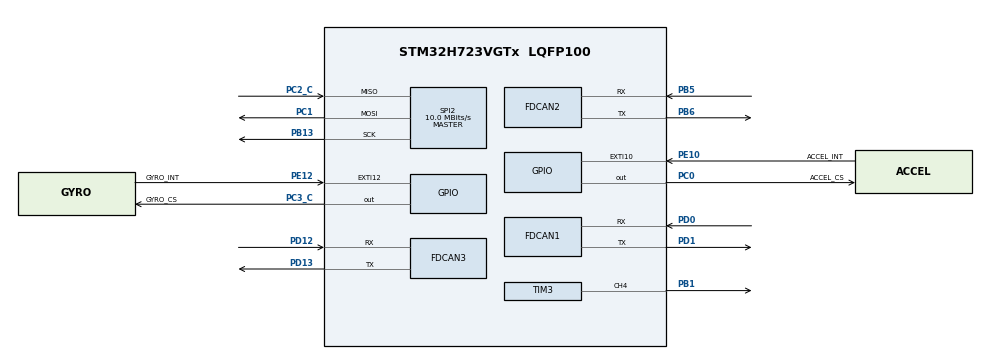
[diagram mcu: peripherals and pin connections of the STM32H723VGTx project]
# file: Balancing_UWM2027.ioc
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CORTEX_M7.AccessPermission_Spec=MPU_REGION_FULL_ACCESS
CORTEX_M7.BaseAddress_Spec=0x24000000
CORTEX_M7.CPU_DCache=Enabled
CORTEX_M7.CPU_ICache=Enabled
CORTEX_M7.DisableExec_Spec=MPU_INSTRUCTION_ACCESS_ENABLE
CORTEX_M7.IsShareable_Spec=MPU_ACCESS_NOT_SHAREABLE
CORTEX_M7.Size_Spec=MPU_REGION_SIZE_512KB
CORTEX_M7.SubRegionDisable_Spec=0x0
CORTEX_M7.TypeExtField_Spec=MPU_TEX_LEVEL1
CORTEX_M7.default_mode_Activation=1
Dma.Request0=UART5_RX
Dma.Request1=SPI2_RX
Dma.Request2=SPI2_TX
Dma.SPI2_RX.1.Direction=DMA_PERIPH_TO_MEMORY
Dma.SPI2_RX.1.EventEnable=DISABLE
Dma.SPI2_RX.1.FIFOMode=DMA_FIFOMODE_DISABLE
Dma.SPI2_RX.1.Instance=DMA1_Stream1
Dma.SPI2_RX.1.MemDataAlignment=DMA_MDATAALIGN_BYTE
Dma.SPI2_RX.1.MemInc=DMA_MINC_ENABLE
Dma.SPI2_RX.1.Mode=DMA_NORMAL
Dma.SPI2_RX.1.PeriphDataAlignment=DMA_PDATAALIGN_BYTE
Dma.SPI2_RX.1.PeriphInc=DMA_PINC_DISABLE
Dma.SPI2_RX.1.Polarity=HAL_DMAMUX_REQ_GEN_RISING
Dma.SPI2_RX.1.Priority=DMA_PRIORITY_VERY_HIGH
Dma.SPI2_RX.1.RequestNumber=1
Dma.SPI2_RX.1.SignalID=NONE
Dma.SPI2_RX.1.SyncEnable=DISABLE
Dma.SPI2_RX.1.SyncPolarity=HAL_DMAMUX_SYNC_NO_EVENT
Dma.SPI2_RX.1.SyncRequestNumber=1
Dma.SPI2_RX.1.SyncSignalID=NONE
Dma.SPI2_TX.2.Direction=DMA_MEMORY_TO_PERIPH
Dma.SPI2_TX.2.EventEnable=DISABLE
Dma.SPI2_TX.2.FIFOMode=DMA_FIFOMODE_DISABLE
Dma.SPI2_TX.2.Instance=DMA1_Stream2
Dma.SPI2_TX.2.MemDataAlignment=DMA_MDATAALIGN_BYTE
Dma.SPI2_TX.2.MemInc=DMA_MINC_ENABLE
Dma.SPI2_TX.2.Mode=DMA_NORMAL
Dma.SPI2_TX.2.PeriphDataAlignment=DMA_PDATAALIGN_BYTE
Dma.SPI2_TX.2.PeriphInc=DMA_PINC_DISABLE
Dma.SPI2_TX.2.Polarity=HAL_DMAMUX_REQ_GEN_RISING
Dma.SPI2_TX.2.Priority=DMA_PRIORITY_MEDIUM
Dma.SPI2_TX.2.RequestNumber=1
Dma.SPI2_TX.2.SignalID=NONE
Dma.SPI2_TX.2.SyncEnable=DISABLE
Dma.SPI2_TX.2.SyncPolarity=HAL_DMAMUX_SYNC_NO_EVENT
Dma.SPI2_TX.2.SyncRequestNumber=1
Dma.SPI2_TX.2.SyncSignalID=NONE
Dma.UART5_RX.0.Direction=DMA_PERIPH_TO_MEMORY
Dma.UART5_RX.0.EventEnable=DISABLE
Dma.UART5_RX.0.FIFOMode=DMA_FIFOMODE_DISABLE
Dma.UART5_RX.0.Instance=DMA1_Stream0
Dma.UART5_RX.0.MemDataAlignment=DMA_MDATAALIGN_BYTE
Dma.UART5_RX.0.MemInc=DMA_MINC_ENABLE
Dma.UART5_RX.0.Mode=DMA_CIRCULAR
Dma.UART5_RX.0.PeriphDataAlignment=DMA_PDATAALIGN_BYTE
Dma.UART5_RX.0.PeriphInc=DMA_PINC_DISABLE
Dma.UART5_RX.0.Polarity=HAL_DMAMUX_REQ_GEN_RISING
Dma.UART5_RX.0.Priority=DMA_PRIORITY_VERY_HIGH
Dma.UART5_RX.0.RequestNumber=1
Dma.UART5_RX.0.SignalID=NONE
Dma.UART5_RX.0.SyncEnable=DISABLE
Dma.UART5_RX.0.SyncPolarity=HAL_DMAMUX_SYNC_NO_EVENT
Dma.UART5_RX.0.SyncRequestNumber=1
Dma.UART5_RX.0.SyncSignalID=NONE
FDCAN1.CalculateBaudRateNominal=1000000
FDCAN1.CalculateTimeBitNominal=1000
FDCAN1.CalculateTimeQuantumNominal=25.0
FDCAN1.DataPrescaler=3
FDCAN1.DataSyncJumpWidth=10
FDCAN1.DataTimeSeg1=29
FDCAN1.DataTimeSeg2=10
FDCAN1.NominalPrescaler=3
FDCAN1.NominalSyncJumpWidth=10
FDCAN1.NominalTimeSeg1=29
FDCAN1.NominalTimeSeg2=10
FDCAN1.ProtocolException=ENABLE
FDCAN1.RxFifo0ElmtsNbr=8
FDCAN1.StdFiltersNbr=1
FDCAN1.TxFifoQueueElmtsNbr=4
FDCAN2.CalculateBaudRateNominal=1000000
FDCAN2.CalculateTimeBitNominal=1000
FDCAN2.CalculateTimeQuantumNominal=25.0
FDCAN2.DataPrescaler=3
FDCAN2.DataSyncJumpWidth=10
FDCAN2.DataTimeSeg1=29
FDCAN2.DataTimeSeg2=10
FDCAN2.MessageRAMOffset=128
FDCAN2.NominalPrescaler=3
FDCAN2.NominalSyncJumpWidth=10
FDCAN2.NominalTimeSeg1=29
FDCAN2.NominalTimeSeg2=10
FDCAN2.ProtocolException=ENABLE
FDCAN2.RxFifo0ElmtsNbr=8
FDCAN2.StdFiltersNbr=1
FDCAN2.TxFifoQueueElmtsNbr=4
FDCAN3.CalculateBaudRateNominal=1000000
FDCAN3.CalculateTimeBitNominal=1000
FDCAN3.CalculateTimeQuantumNominal=25.0
FDCAN3.DataPrescaler=3
FDCAN3.DataSyncJumpWidth=10
FDCAN3.DataTimeSeg1=29
FDCAN3.DataTimeSeg2=10
FDCAN3.MessageRAMOffset=256
FDCAN3.NominalPrescaler=3
FDCAN3.NominalSyncJumpWidth=10
FDCAN3.NominalTimeSeg1=29
FDCAN3.NominalTimeSeg2=10
FDCAN3.ProtocolException=ENABLE
FDCAN3.RxFifo0ElmtsNbr=8
FDCAN3.StdFiltersNbr=1
FDCAN3.TxFifoQueueElmtsNbr=4
FREERTOS.Tasks01=defaultTask,24,128,StartDefaultTask,Default,NULL,Dynamic,NULL,NULL
FREERTOS.configTOTAL_HEAP_SIZE=32768
Mcu.Family=STM32H7
Mcu.Name=STM32H723VGTx
Mcu.Package=LQFP100
NVIC.DMA1_Stream0_IRQn=true\:5\:0\:false\:false\:true\:true\:false\:true\:true
NVIC.DMA1_Stream1_IRQn=true\:5\:0\:false\:false\:true\:true\:false\:true\:true
NVIC.DMA1_Stream2_IRQn=true\:5\:0\:false\:false\:true\:true\:false\:true\:true
NVIC.FDCAN1_IT0_IRQn=true\:5\:0\:false\:false\:true\:true\:true\:true\:true
NVIC.FDCAN2_IT0_IRQn=true\:5\:0\:false\:false\:true\:true\:true\:true\:true
NVIC.FDCAN3_IT0_IRQn=true\:5\:0\:false\:false\:true\:true\:true\:true\:true
NVIC.PriorityGroup=NVIC_PRIORITYGROUP_4
NVIC.SPI2_IRQn=true\:5\:0\:false\:false\:true\:true\:false\:true\:true
NVIC.TIM2_IRQn=true\:15\:0\:false\:false\:true\:false\:false\:true\:true
NVIC.TimeBase=TIM2_IRQn
NVIC.TimeBaseIP=TIM2
PB1.Signal=S_TIM3_CH4
PB13.Mode=Full_Duplex_Master
PB13.Signal=SPI2_SCK
PB5.Mode=FDCAN_Activate
PB5.Signal=FDCAN2_RX
PB6.Mode=FDCAN_Activate
PB6.Signal=FDCAN2_TX
PC0.GPIO_Label=ACCEL_CS
PC0.GPIO_Speed=GPIO_SPEED_FREQ_MEDIUM
PC0.PinState=GPIO_PIN_SET
PC0.Signal=GPIO_Output
PC1.Mode=Full_Duplex_Master
PC1.Signal=SPI2_MOSI
PC2_C.Mode=Full_Duplex_Master
PC2_C.Signal=SPI2_MISO
PC3_C.GPIO_Label=GYRO_CS
PC3_C.GPIO_Speed=GPIO_SPEED_FREQ_MEDIUM
PC3_C.PinState=GPIO_PIN_SET
PC3_C.Signal=GPIO_Output
PD0.Mode=FDCAN_Activate
PD0.Signal=FDCAN1_RX
PD1.Mode=FDCAN_Activate
PD1.Signal=FDCAN1_TX
PD12.Mode=FDCAN_Activate
PD12.Signal=FDCAN3_RX
PD13.Mode=FDCAN_Activate
PD13.Signal=FDCAN3_TX
PD2.Signal=UART5_RX
PE10.GPIO_Label=ACCEL_INT
PE10.GPIO_ModeDefaultEXTI=GPIO_MODE_IT_RISING
PE10.Signal=GPXTI10
PE12.GPIO_Label=GYRO_INT
PE12.Signal=GPXTI12
PH0-OSC_IN.Mode=HSE-External-Oscillator
PH0-OSC_IN.Signal=RCC_OSC_IN
PH1-OSC_OUT.Mode=HSE-External-Oscillator
PH1-OSC_OUT.Signal=RCC_OSC_OUT
ProjectManager.HeapSize=0x200
ProjectManager.StackSize=0x400
ProjectManager.TargetToolchain=MDK-ARM V5.32
RCC.ADCFreq_Value=100000000
RCC.APB1Freq_Value=120000000
RCC.APB2Freq_Value=120000000
RCC.APB3Freq_Value=120000000
RCC.APB4Freq_Value=120000000
RCC.CortexFreq_Value=480000000
RCC.D1PPRE=RCC_APB3_DIV2
RCC.D2PPRE1=RCC_APB1_DIV2
RCC.D2PPRE2=RCC_APB2_DIV2
RCC.D3PPRE=RCC_APB4_DIV2
RCC.DIVM1=2
RCC.DIVM2=24
RCC.DIVM3=24
RCC.DIVN1=40
RCC.DIVN2=200
RCC.DIVN3=160
RCC.DIVP1=1
RCC.DIVQ1=4
RCC.HCLKFreq_Value=240000000
RCC.HPRE=RCC_HCLK_DIV2
RCC.HSE_VALUE=24000000
RCC.PLLSourceVirtual=RCC_PLLSOURCE_HSE
RCC.SPI123CLockSelection=RCC_SPI123CLKSOURCE_PLL3
RCC.SYSCLKFreq_VALUE=480000000
RCC.SYSCLKSource=RCC_SYSCLKSOURCE_PLLCLK
RCC.USBFreq_Value=120000000
SH.S_TIM3_CH4.0=TIM3_CH4,PWM Generation4 CH4
SPI2.BaudRatePrescaler=SPI_BAUDRATEPRESCALER_8
SPI2.CLKPhase=SPI_PHASE_2EDGE
SPI2.CLKPolarity=SPI_POLARITY_HIGH
SPI2.CalculateBaudRate=10.0 MBits/s
SPI2.DataSize=SPI_DATASIZE_8BIT
SPI2.Direction=SPI_DIRECTION_2LINES
SPI2.Mode=SPI_MODE_MASTER
SPI2.NSSPMode=SPI_NSS_PULSE_DISABLE
SPI2.VirtualType=VM_MASTER
TIM3.AutoReloadPreload=TIM_AUTORELOAD_PRELOAD_ENABLE
TIM3.Channel-PWM\ Generation4\ CH4=TIM_CHANNEL_4
TIM3.Period=20000
TIM3.Prescaler=80-1
VP_FREERTOS_VS_CMSIS_V2.Mode=CMSIS_V2
VP_MEMORYMAP_VS_MEMORYMAP.Mode=CurAppReg
VP_SYS_VS_tim2.Mode=TIM2
board=custom

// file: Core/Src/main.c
/* USER CODE BEGIN Header */
/**
  ******************************************************************************
  * @file           : main.c
  * @brief          : Main program body
  ******************************************************************************
  * @attention
  *
  * Copyright (c) 2026 STMicroelectronics.
  * All rights reserved.
  *
  * This software is licensed under terms that can be found in the LICENSE file
  * in the root directory of this software component.
  * If no LICENSE file comes with this software, it is provided AS-IS.
  *
  ******************************************************************************
  */
/* USER CODE END Header */
#include "main.h"
#include "FreeRTOS.h"
#include "cmsis_os2.h"
#include "dma.h"
#include "fdcan.h"
#include "spi.h"
#include "tim.h"
#include "gpio.h"

/* USER CODE BEGIN Includes */
#include "bsp_can.h"
#include  "fdcan_motor.h"
#include "bsp_mcu.h"
/* USER CODE END Includes */

void SystemClock_Config(void);
static void MPU_Config(void);
void MX_FREERTOS_Init(void);

int main(void)
{

  /* MPU Configuration--------------------------------------------------------*/
  MPU_Config();

  /* Enable the CPU Cache */

  /* Enable I-Cache---------------------------------------------------------*/
  SCB_EnableICache();

  /* Enable D-Cache---------------------------------------------------------*/
  SCB_EnableDCache();

  /* MCU Configuration--------------------------------------------------------*/

  /* Reset of all peripherals, Initializes the Flash interface and the Systick. */
  HAL_Init();

  /* Configure the system clock */
  SystemClock_Config();

  /* Initialize all configured peripherals */
  MX_GPIO_Init();
  MX_DMA_Init();
  MX_FDCAN1_Init();
  MX_FDCAN2_Init();
  MX_FDCAN3_Init();
  MX_SPI2_Init();
  MX_TIM3_Init();
  /* USER CODE BEGIN 2 */
  MCU_Init();
  /* USER CODE END 2 */

  /* Init scheduler */
  osKernelInitialize();  /* Call init function for freertos objects (in cmsis_os2.c) */
  MX_FREERTOS_Init();

  /* Start scheduler */
  osKernelStart();

  /* We should never get here as control is now taken by the scheduler */

  /* Infinite loop */
  while (1)
  {

    /* USER CODE BEGIN 3 */
    FDCAN_cmd_chassis(0, 0, 0, 0, 0, 0);
    HAL_Delay(10);
  }
  /* USER CODE END 3 */
}

void SystemClock_Config(void)
{
  RCC_OscInitTypeDef RCC_OscInitStruct = {0};
  RCC_ClkInitTypeDef RCC_ClkInitStruct = {0};

  /** Supply configuration update enable
  */
  HAL_PWREx_ConfigSupply(PWR_LDO_SUPPLY);

  /** Configure the main internal regulator output voltage
  */
  __HAL_PWR_VOLTAGESCALING_CONFIG(PWR_REGULATOR_VOLTAGE_SCALE0);

  while(!__HAL_PWR_GET_FLAG(PWR_FLAG_VOSRDY)) {}

  /** Initializes the RCC Oscillators according to the specified parameters
  * in the RCC_OscInitTypeDef structure.
  */
  RCC_OscInitStruct.OscillatorType = RCC_OSCILLATORTYPE_HSE;
  RCC_OscInitStruct.HSEState = RCC_HSE_ON;
  RCC_OscInitStruct.PLL.PLLState = RCC_PLL_ON;
  RCC_OscInitStruct.PLL.PLLSource = RCC_PLLSOURCE_HSE;
  RCC_OscInitStruct.PLL.PLLM = 2;
  RCC_OscInitStruct.PLL.PLLN = 40;
  RCC_OscInitStruct.PLL.PLLP = 1;
  RCC_OscInitStruct.PLL.PLLQ = 4;
  RCC_OscInitStruct.PLL.PLLR = 2;
  RCC_OscInitStruct.PLL.PLLRGE = RCC_PLL1VCIRANGE_3;
  RCC_OscInitStruct.PLL.PLLVCOSEL = RCC_PLL1VCOWIDE;
  RCC_OscInitStruct.PLL.PLLFRACN = 0;
  if (HAL_RCC_OscConfig(&RCC_OscInitStruct) != HAL_OK)
  {
    Error_Handler();
  }

  /** Initializes the CPU, AHB and APB buses clocks
  */
  RCC_ClkInitStruct.ClockType = RCC_CLOCKTYPE_HCLK|RCC_CLOCKTYPE_SYSCLK
                              |RCC_CLOCKTYPE_PCLK1|RCC_CLOCKTYPE_PCLK2
                              |RCC_CLOCKTYPE_D3PCLK1|RCC_CLOCKTYPE_D1PCLK1;
  RCC_ClkInitStruct.SYSCLKSource = RCC_SYSCLKSOURCE_PLLCLK;
  RCC_ClkInitStruct.SYSCLKDivider = RCC_SYSCLK_DIV1;
  RCC_ClkInitStruct.AHBCLKDivider = RCC_HCLK_DIV2;
  RCC_ClkInitStruct.APB3CLKDivider = RCC_APB3_DIV2;
  RCC_ClkInitStruct.APB1CLKDivider = RCC_APB1_DIV2;
  RCC_ClkInitStruct.APB2CLKDivider = RCC_APB2_DIV2;
  RCC_ClkInitStruct.APB4CLKDivider = RCC_APB4_DIV2;

  if (HAL_RCC_ClockConfig(&RCC_ClkInitStruct, FLASH_LATENCY_3) != HAL_OK)
  {
    Error_Handler();
  }
}

 /* MPU Configuration */

void MPU_Config(void)
{
  MPU_Region_InitTypeDef MPU_InitStruct = {0};

  /* Disables the MPU */
  HAL_MPU_Disable();

  /** Initializes and configures the Region and the memory to be protected
  */
  MPU_InitStruct.Enable = MPU_REGION_ENABLE;
  MPU_InitStruct.Number = MPU_REGION_NUMBER0;
  MPU_InitStruct.BaseAddress = 0x24000000;
  MPU_InitStruct.Size = MPU_REGION_SIZE_512KB;
  MPU_InitStruct.SubRegionDisable = 0x0;
  MPU_InitStruct.TypeExtField = MPU_TEX_LEVEL1;
  MPU_InitStruct.AccessPermission = MPU_REGION_FULL_ACCESS;
  MPU_InitStruct.DisableExec = MPU_INSTRUCTION_ACCESS_ENABLE;
  MPU_InitStruct.IsShareable = MPU_ACCESS_NOT_SHAREABLE;
  MPU_InitStruct.IsCacheable = MPU_ACCESS_NOT_CACHEABLE;
  MPU_InitStruct.IsBufferable = MPU_ACCESS_NOT_BUFFERABLE;

  HAL_MPU_ConfigRegion(&MPU_InitStruct);
  /* Enables the MPU */
  HAL_MPU_Enable(MPU_PRIVILEGED_DEFAULT);

}

void HAL_TIM_PeriodElapsedCallback(TIM_HandleTypeDef *htim)
{
  if (htim->Instance == TIM2)
  {
    HAL_IncTick();
  }
}

void Error_Handler(void)
{
  __disable_irq();
  while (1)
  {
  }
}

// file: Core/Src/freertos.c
/* USER CODE BEGIN Header */
/**
  ******************************************************************************
  * File Name          : freertos.c
  * Description        : Code for freertos applications
  ******************************************************************************
  * @attention
  *
  * Copyright (c) 2026 STMicroelectronics.
  * All rights reserved.
  *
  * This software is licensed under terms that can be found in the LICENSE file
  * in the root directory of this software component.
  * If no LICENSE file comes with this software, it is provided AS-IS.
  *
  ******************************************************************************
  */
/* USER CODE END Header */

#include "FreeRTOS.h"
#include "task.h"
#include "main.h"
#include "cmsis_os2.h"

/* USER CODE BEGIN Includes */
#include "INS_Task.h"
/* USER CODE END Includes */

/* USER CODE BEGIN Variables */
osThreadId_t Start_INS_TaskHandle;
const osThreadAttr_t Start_INS_Task_attributes = {.name = "Start_INS_Task", .stack_size = 2048 * 4, .priority = (osPriority_t)osPriorityHigh};
/* USER CODE END Variables */
/* Definitions for defaultTask */
osThreadId_t defaultTaskHandle;
const osThreadAttr_t defaultTask_attributes = {
  .name = "defaultTask",
  .stack_size = 128 * 4,
  .priority = (osPriority_t) osPriorityNormal,
};

void StartDefaultTask(void *argument);

void MX_FREERTOS_Init(void); /* (MISRA C 2004 rule 8.1) */

void MX_FREERTOS_Init(void) {

  /* Create the thread(s) */
  /* creation of defaultTask */
  defaultTaskHandle = osThreadNew(StartDefaultTask, NULL, &defaultTask_attributes);

  /* USER CODE BEGIN RTOS_THREADS */
  Start_INS_TaskHandle = osThreadNew(INS_Task, NULL, &Start_INS_Task_attributes);
  /* USER CODE END RTOS_THREADS */

}

void StartDefaultTask(void *argument)
{
  for(;;)
  {
    osDelay(1);
  }
}
